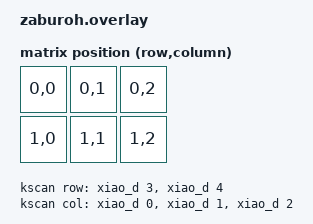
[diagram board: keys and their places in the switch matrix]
// This file was generated from a template. Edit it to match your keyboard.
// See https://zmk.dev/docs/development/hardware-integration/new-shield for more
// instructions.

#include <dt-bindings/zmk/matrix_transform.h>

#include "zaburoh-layouts.dtsi"

/ {
    chosen {
        zmk,physical-layout = &default_layout;
        zmk,matrix-transform = &default_transform;
        zmk,kscan = &kscan;
    };

    kscan: kscan {
        // If the hardware does not use a switch matrix, change this to the
        // appropriate driver and update the properties below to match.
        // See https://zmk.dev/docs/config/kscan for supported key scan drivers.
        compatible = "zmk,kscan-gpio-matrix";
        // Set this to "col2row" or "row2col" to match the hardware. If using
        // "row2col", change the col-gpios to (GPIO_ACTIVE_HIGH | GPIO_PULL_DOWN)
        // and the row-gpios to GPIO_ACTIVE_HIGH.
        diode-direction = "col2row";
        wakeup-source;

        // Replace these comments with the GPIO pins in the matrix.
        // See https://zmk.dev/docs/development/hardware-integration/new-shield#shield-overlays
        col-gpios
            = <&xiao_d 0 GPIO_ACTIVE_LOW>
            , <&xiao_d 1 GPIO_ACTIVE_LOW>
            , <&xiao_d 2 GPIO_ACTIVE_LOW>
            ;

        row-gpios
            = <&xiao_d 3 (GPIO_ACTIVE_LOW | GPIO_PULL_UP)>
            , <&xiao_d 4 (GPIO_ACTIVE_LOW | GPIO_PULL_UP)>
            ;
    };

    default_transform: default_transform {
        // See https://zmk.dev/docs/development/hardware-integration/new-shield#matrix-transform
        // for how to configure this
        compatible = "zmk,matrix-transform";
        columns = <3>;
        rows = <2>;

        map = <
            RC(0, 0) RC(0, 1) RC(0, 2)
            RC(1, 0) RC(1, 1) RC(1, 2)
        >;
    };
};
